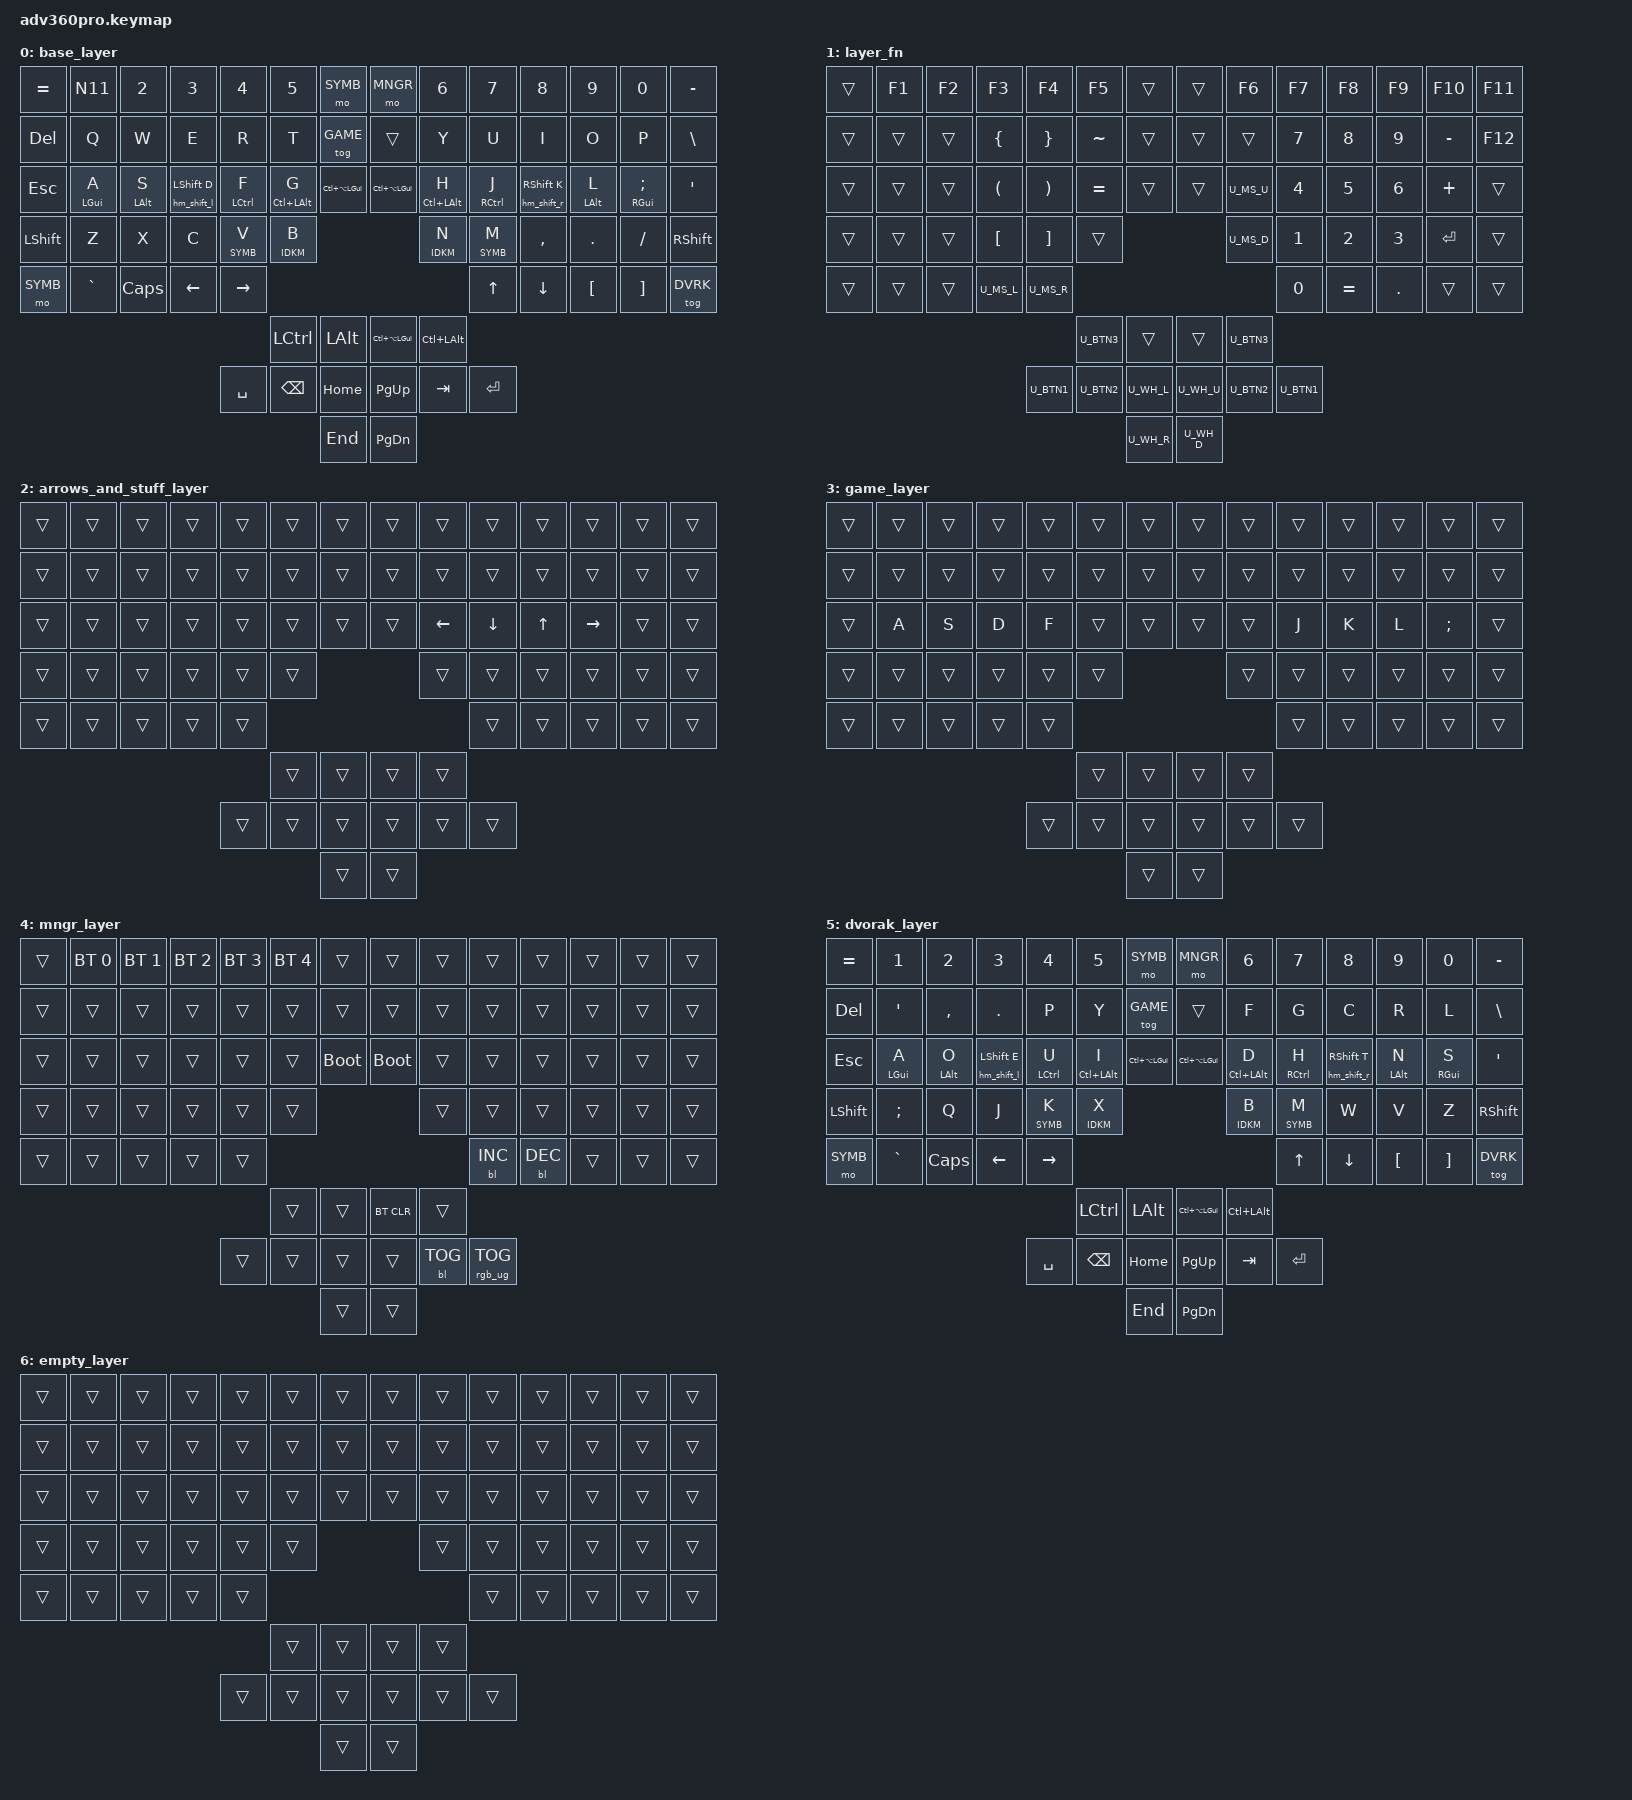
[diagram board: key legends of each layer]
#include <behaviors.dtsi>
#include <dt-bindings/zmk/keys.h>
#include <dt-bindings/zmk/bt.h>
#include <dt-bindings/zmk/outputs.h>
#include <dt-bindings/zmk/rgb.h>
#include <dt-bindings/zmk/backlight.h>
#include "includes/behaviours_homerow_mods.dtsi"

/* definitions for mouse layer */
#include "mouse.dtsi"

#define ___ &trans
#define DFLT 0
#define SYMB 1
#define IDKM 2
#define GAME 3
#define MNGR 4
#define DVRK 5

/ {
    /* remove unused keys from layout and move thumb cluster to bottom */
    chosen {
        zmk,matrix_transform = &urobs_transform;
    };

    keymap {
        compatible = "zmk,keymap";

        base_layer {
            bindings = <
// ╭────────────────────┬────────────────────┬────────────────────┬────────────────────┬────────────────────┬────────────────────┬────────────────────╮ ╭────────────────────┬────────────────────┬────────────────────┬────────────────────┬────────────────────┬────────────────────┬────────────────────╮
    &kp EQUAL            &kp N11               &kp N2               &kp N3               &kp N4               &kp N5               &mo SYMB               &mo MNGR             &kp N6                &kp N7              &kp N8               &kp N9               &kp N0               &kp MINUS
// ├────────────────────┼────────────────────┼────────────────────┼────────────────────┼────────────────────┼────────────────────┼────────────────────┤ ├────────────────────┼────────────────────┼────────────────────┼────────────────────┼────────────────────┼────────────────────┼────────────────────┤
    &kp DEL              &kp Q                &kp W                 &kp E               &kp R                &kp T                &tog GAME              ___                  &kp Y                &kp U                &kp I                &kp O                &kp P                &kp BSLH
// ├────────────────────┼────────────────────┼────────────────────┼────────────────────┼────────────────────┼────────────────────┼────────────────────┤ ├────────────────────┼────────────────────┼────────────────────┼────────────────────┼────────────────────┼────────────────────┼────────────────────┤
    &kp ESC              &hm_l LGUI A         &hm_l LALT S         &hm_shift_l LSHFT D  &hm_l LCTRL F        &hm_l LC(LALT) G     &kp LC(LA(LGUI))       &kp LC(LA(LGUI))     &hm_r LC(LALT) H     &hm_r RCTRL J        &hm_shift_r RSHFT K  &hm_r LALT L         &hm_r RGUI SEMI      &kp SQT
// ├────────────────────┼────────────────────┼────────────────────┼────────────────────┼────────────────────┼────────────────────┴────────────────────╯ ╰────────────────────┼────────────────────┼────────────────────┼────────────────────┼────────────────────┼────────────────────┼────────────────────┤
    &kp LSHFT            &kp Z                &kp X                &kp C                &lt_l SYMB V         &lt_l IDKM B                                                     &lt_r IDKM N         &lt_r SYMB M         &kp COMMA            &kp DOT              &kp FSLH             &kp RSHFT
// ├────────────────────┼────────────────────┼────────────────────┼────────────────────┼────────────────────┼────────────────────╯                                           ╰────────────────────┼────────────────────┼────────────────────┼────────────────────┼────────────────────┼────────────────────┤
    &mo SYMB            &kp GRAVE             &kp CAPS              &kp LEFT             &kp RIGHT                                                                                                 &kp UP               &kp DOWN             &kp LBKT             &kp RBKT             &tog DVRK
// ╰────────────────────┴────────────────────┴────────────────────┴────────────────────┴────────────────────╯                                                                                     ╰────────────────────┴────────────────────┴────────────────────┴────────────────────┴────────────────────╯
//                                                                                                          ╭────────────────────┬────────────────────╮ ╭────────────────────┬────────────────────╮
                                                                                                             &kp LCTRL            &kp LALT               &kp LC(LA(LGUI))     &kp LC(LALT)
//                                                                                     ╭────────────────────┼────────────────────┼────────────────────┤ ├────────────────────┼────────────────────┼────────────────────╮
                                                                                         &kp SPACE           &kp BSPC             &kp HOME                &kp PG_UP           &kp TAB               &kp ENTER
//                                                                                     │                    │                    ├────────────────────┤ ├────────────────────┤                    │                    │
                                                                                                                                  &kp END                 &kp PG_DN
//                                                                                     ╰────────────────────┴────────────────────┴────────────────────╯ ╰────────────────────┴────────────────────┴────────────────────╯
            >;
        };

        layer_fn {
            bindings = <
// ╭────────────────────┬────────────────────┬────────────────────┬────────────────────┬────────────────────┬────────────────────┬────────────────────╮ ╭────────────────────┬────────────────────┬────────────────────┬────────────────────┬────────────────────┬────────────────────┬────────────────────╮
    ___                  &kp F1               &kp F2               &kp F3               &kp F4               &kp F5               ___                    ___                  &kp F6               &kp F7               &kp F8               &kp F9               &kp F10              &kp F11
// ├────────────────────┼────────────────────┼────────────────────┼────────────────────┼────────────────────┼────────────────────┼────────────────────┤ ├────────────────────┼────────────────────┼────────────────────┼────────────────────┼────────────────────┼────────────────────┼────────────────────┤
    ___                  ___                  ___                  &kp LBRC             &kp RBRC             &kp TILDE            ___                    ___                  ___                  &kp N7               &kp N8               &kp N9               &kp MINUS            &kp F12
// ├────────────────────┼────────────────────┼────────────────────┼────────────────────┼────────────────────┼────────────────────┼────────────────────┤ ├────────────────────┼────────────────────┼────────────────────┼────────────────────┼────────────────────┼────────────────────┼────────────────────┤
    ___                  ___                  ___                  &kp LPAR             &kp RPAR             &kp EQUAL            ___                    ___                  U_MS_U               &kp N4               &kp N5               &kp N6               &kp PLUS             ___
// ├────────────────────┼────────────────────┼────────────────────┼────────────────────┼────────────────────┼────────────────────┴────────────────────╯ ╰────────────────────┼────────────────────┼────────────────────┼────────────────────┼────────────────────┼────────────────────┼────────────────────┤
    ___                  ___                  ___                  &kp LBKT             &kp RBKT             ___                                                              U_MS_D               &kp N1               &kp N2               &kp N3               &kp ENTER            ___
// ├────────────────────┼────────────────────┼────────────────────┼────────────────────┼────────────────────┼────────────────────╯                                           ╰────────────────────┼────────────────────┼────────────────────┼────────────────────┼────────────────────┼────────────────────┤
    ___                  ___                  ___                  U_MS_L               U_MS_R                                                                                                     &kp N0               &kp EQUAL            &kp DOT              ___                  ___
// ╰────────────────────┴────────────────────┴────────────────────┴────────────────────┴────────────────────╯                                                                                     ╰────────────────────┴────────────────────┴────────────────────┴────────────────────┴────────────────────╯
//                                                                                                          ╭────────────────────┬────────────────────╮ ╭────────────────────┬────────────────────╮
                                                                                                             U_BTN3               ___                    ___                  U_BTN3
//                                                                                     ╭────────────────────┼────────────────────┼────────────────────┤ ├────────────────────┼────────────────────┼────────────────────╮
                                                                                         U_BTN1              U_BTN2               U_WH_L                 U_WH_U               U_BTN2                U_BTN1
//                                                                                     │                    │                    ├────────────────────┤ ├────────────────────┤                    │                    │
                                                                                                                                  U_WH_R                 U_WH_D
//                                                                                     ╰────────────────────┴────────────────────┴────────────────────╯ ╰────────────────────┴────────────────────┴────────────────────╯
            >;
        };

// wtf else goes on this layer? i only need arrows for a couple things and the thumb arrows are goofy ahh
        arrows_and_stuff_layer {
            bindings = <
// ╭────────────────────┬────────────────────┬────────────────────┬────────────────────┬────────────────────┬────────────────────┬────────────────────╮ ╭────────────────────┬────────────────────┬────────────────────┬────────────────────┬────────────────────┬────────────────────┬────────────────────╮
    ___                  ___                  ___                  ___                  ___                  ___                  ___                    ___                  ___                  ___                  ___                  ___                  ___                  ___
// ├────────────────────┼────────────────────┼────────────────────┼────────────────────┼────────────────────┼────────────────────┼────────────────────┤ ├────────────────────┼────────────────────┼────────────────────┼────────────────────┼────────────────────┼────────────────────┼────────────────────┤
    ___                  ___                  ___                  ___                  ___                  ___                  ___                    ___                  ___                  ___                  ___                  ___                  ___                  ___
// ├────────────────────┼────────────────────┼────────────────────┼────────────────────┼────────────────────┼────────────────────┼────────────────────┤ ├────────────────────┼────────────────────┼────────────────────┼────────────────────┼────────────────────┼────────────────────┼────────────────────┤
    ___                  ___                  ___                  ___                  ___                  ___                  ___                    ___                  &kp LEFT             &kp DOWN             &kp UP               &kp RIGHT            ___                  ___
// ├────────────────────┼────────────────────┼────────────────────┼────────────────────┼────────────────────┼────────────────────┴────────────────────╯ ╰────────────────────┼────────────────────┼────────────────────┼────────────────────┼────────────────────┼────────────────────┼────────────────────┤
    ___                  ___                  ___                  ___                  ___                  ___                                                              ___                  ___                  ___                  ___                  ___                  ___
// ├────────────────────┼────────────────────┼────────────────────┼────────────────────┼────────────────────┼────────────────────╯                                           ╰────────────────────┼────────────────────┼────────────────────┼────────────────────┼────────────────────┼────────────────────┤
    ___                  ___                  ___                  ___                  ___                                                                                                        ___                  ___                  ___                  ___                  ___
// ╰────────────────────┴────────────────────┴────────────────────┴────────────────────┴────────────────────╯                                                                                     ╰────────────────────┴────────────────────┴────────────────────┴────────────────────┴────────────────────╯
//                                                                                                          ╭────────────────────┬────────────────────╮ ╭────────────────────┬────────────────────╮
                                                                                                             ___                  ___                    ___                  ___
//                                                                                     ╭────────────────────┼────────────────────┼────────────────────┤ ├────────────────────┼────────────────────┼────────────────────╮
                                                                                         ___                 ___                  ___                    ___                  ___                   ___
//                                                                                     │                    │                    ├────────────────────┤ ├────────────────────┤                    │                    │
                                                                                                                                  ___                    ___
//                                                                                     ╰────────────────────┴────────────────────┴────────────────────╯ ╰────────────────────┴────────────────────┴────────────────────╯
            >;
        };



// game layer just gets rid of home row mods because thats cancer for playing games
        game_layer {
            bindings = <
// ╭────────────────────┬────────────────────┬────────────────────┬────────────────────┬────────────────────┬────────────────────┬────────────────────╮ ╭────────────────────┬────────────────────┬────────────────────┬────────────────────┬────────────────────┬────────────────────┬────────────────────╮
    ___                  ___                  ___                  ___                  ___                  ___                  ___                    ___                  ___                  ___                  ___                  ___                  ___                  ___
// ├────────────────────┼────────────────────┼────────────────────┼────────────────────┼────────────────────┼────────────────────┼────────────────────┤ ├────────────────────┼────────────────────┼────────────────────┼────────────────────┼────────────────────┼────────────────────┼────────────────────┤
    ___                  ___                  ___                  ___                  ___                  ___                  ___                    ___                  ___                  ___                  ___                  ___                  ___                  ___
// ├────────────────────┼────────────────────┼────────────────────┼────────────────────┼────────────────────┼────────────────────┼────────────────────┤ ├────────────────────┼────────────────────┼────────────────────┼────────────────────┼────────────────────┼────────────────────┼────────────────────┤
    ___                  &kp A                &kp S                &kp D                &kp F                ___                  ___                    ___                  ___                  &kp J                &kp K                &kp L                &kp SEMI             ___
// ├────────────────────┼────────────────────┼────────────────────┼────────────────────┼────────────────────┼────────────────────┴────────────────────╯ ╰────────────────────┼────────────────────┼────────────────────┼────────────────────┼────────────────────┼────────────────────┼────────────────────┤
    ___                  ___                  ___                  ___                  ___                  ___                                                              ___                  ___                  ___                  ___                  ___                  ___
// ├────────────────────┼────────────────────┼────────────────────┼────────────────────┼────────────────────┼────────────────────╯                                           ╰────────────────────┼────────────────────┼────────────────────┼────────────────────┼────────────────────┼────────────────────┤
    ___                  ___                  ___                  ___                  ___                                                                                                        ___                  ___                  ___                  ___                  ___
// ╰────────────────────┴────────────────────┴────────────────────┴────────────────────┴────────────────────╯                                                                                     ╰────────────────────┴────────────────────┴────────────────────┴────────────────────┴────────────────────╯
//                                                                                                          ╭────────────────────┬────────────────────╮ ╭────────────────────┬────────────────────╮
                                                                                                             ___                  ___                    ___                  ___
//                                                                                     ╭────────────────────┼────────────────────┼────────────────────┤ ├────────────────────┼────────────────────┼────────────────────╮
                                                                                         ___                 ___                  ___                    ___                  ___                   ___
//                                                                                     │                    │                    ├────────────────────┤ ├────────────────────┤                    │                    │
                                                                                                                                  ___                    ___
//                                                                                     ╰────────────────────┴────────────────────┴────────────────────╯ ╰────────────────────┴────────────────────┴────────────────────╯
            >;
        };

        mngr_layer {
            bindings = <
// ╭────────────────────┬────────────────────┬────────────────────┬────────────────────┬────────────────────┬────────────────────┬────────────────────╮ ╭────────────────────┬────────────────────┬────────────────────┬────────────────────┬────────────────────┬────────────────────┬────────────────────╮
    ___                  &bt BT_SEL 0         &bt BT_SEL 1         &bt BT_SEL 2         &bt BT_SEL 3         &bt BT_SEL 4         ___                    ___                  ___                  ___                  ___                  ___                  ___                  ___
// ├────────────────────┼────────────────────┼────────────────────┼────────────────────┼────────────────────┼────────────────────┼────────────────────┤ ├────────────────────┼────────────────────┼────────────────────┼────────────────────┼────────────────────┼────────────────────┼────────────────────┤
    ___                  ___                  ___                  ___                  ___                  ___                  ___                    ___                  ___                  ___                  ___                  ___                  ___                  ___
// ├────────────────────┼────────────────────┼────────────────────┼────────────────────┼────────────────────┼────────────────────┼────────────────────┤ ├────────────────────┼────────────────────┼────────────────────┼────────────────────┼────────────────────┼────────────────────┼────────────────────┤
    ___                  ___                  ___                  ___                  ___                  ___                  &bootloader            &bootloader           ___                  ___                  ___                  ___                  ___                  ___
// ├────────────────────┼────────────────────┼────────────────────┼────────────────────┼────────────────────┼────────────────────┴────────────────────╯ ╰────────────────────┼────────────────────┼────────────────────┼────────────────────┼────────────────────┼────────────────────┼────────────────────┤
    ___                  ___                  ___                  ___                  ___                  ___                                                              ___                  ___                  ___                  ___                  ___                  ___
// ├────────────────────┼────────────────────┼────────────────────┼────────────────────┼────────────────────┼────────────────────╯                                           ╰────────────────────┼────────────────────┼────────────────────┼────────────────────┼────────────────────┼────────────────────┤
    ___                  ___                  ___                  ___                  ___                                                                                                        &bl BL_INC           &bl BL_DEC           ___                  ___                  ___
// ╰────────────────────┴────────────────────┴────────────────────┴────────────────────┴────────────────────╯                                                                                     ╰────────────────────┴────────────────────┴────────────────────┴────────────────────┴────────────────────╯
//                                                                                                          ╭────────────────────┬────────────────────╮ ╭────────────────────┬────────────────────╮
                                                                                                             ___                  ___                    &bt BT_CLR           ___
//                                                                                     ╭────────────────────┼────────────────────┼────────────────────┤ ├────────────────────┼────────────────────┼────────────────────╮
                                                                                         ___                 ___                  ___                    ___                  &bl BL_TOG           &rgb_ug RGB_TOG
//                                                                                     │                    │                    ├────────────────────┤ ├────────────────────┤                    │                    │
                                                                                                                                  ___                    ___
//                                                                                     ╰────────────────────┴────────────────────┴────────────────────╯ ╰────────────────────┴────────────────────┴────────────────────╯
            >;
        };

        dvorak_layer {
            bindings = <
// ╭────────────────────┬────────────────────┬────────────────────┬────────────────────┬────────────────────┬────────────────────┬────────────────────╮ ╭────────────────────┬────────────────────┬────────────────────┬────────────────────┬────────────────────┬────────────────────┬────────────────────╮
    &kp EQUAL            &kp N1               &kp N2               &kp N3               &kp N4               &kp N5               &mo SYMB               &mo MNGR             &kp N6                &kp N7              &kp N8               &kp N9               &kp N0               &kp MINUS
// ├────────────────────┼────────────────────┼────────────────────┼────────────────────┼────────────────────┼────────────────────┼────────────────────┤ ├────────────────────┼────────────────────┼────────────────────┼────────────────────┼────────────────────┼────────────────────┼────────────────────┤
    &kp DEL              &kp SQT              &kp COMMA            &kp DOT              &kp P                &kp Y                &tog GAME              ___                  &kp F                &kp G                &kp C                &kp R                &kp L                &kp BSLH
// ├────────────────────┼────────────────────┼────────────────────┼────────────────────┼────────────────────┼────────────────────┼────────────────────┤ ├────────────────────┼────────────────────┼────────────────────┼────────────────────┼────────────────────┼────────────────────┼────────────────────┤
    &kp ESC              &hm_l LGUI A         &hm_l LALT O         &hm_shift_l LSHFT E  &hm_l LCTRL U        &hm_l LC(LALT) I     &kp LC(LA(LGUI))       &kp LC(LA(LGUI))     &hm_r LC(LALT) D     &hm_r RCTRL H        &hm_shift_r RSHFT T  &hm_r LALT N         &hm_r RGUI S         &kp SQT
// ├────────────────────┼────────────────────┼────────────────────┼────────────────────┼────────────────────┼────────────────────┴────────────────────╯ ╰────────────────────┼────────────────────┼────────────────────┼────────────────────┼────────────────────┼────────────────────┼────────────────────┤
    &kp LSHFT            &kp SEMI             &kp Q                &kp J                &lt_l SYMB K         &lt_l IDKM X                                                     &lt_r IDKM B         &lt_r SYMB M         &kp W                &kp V                &kp Z                &kp RSHFT
// ├────────────────────┼────────────────────┼────────────────────┼────────────────────┼────────────────────┼────────────────────╯                                           ╰────────────────────┼────────────────────┼────────────────────┼────────────────────┼────────────────────┼────────────────────┤
    &mo SYMB            &kp GRAVE             &kp CAPS              &kp LEFT             &kp RIGHT                                                                                                 &kp UP               &kp DOWN             &kp LBKT             &kp RBKT             &tog DVRK
// ╰────────────────────┴────────────────────┴────────────────────┴────────────────────┴────────────────────╯                                                                                     ╰────────────────────┴────────────────────┴────────────────────┴────────────────────┴────────────────────╯
//                                                                                                          ╭────────────────────┬────────────────────╮ ╭────────────────────┬────────────────────╮
                                                                                                             &kp LCTRL            &kp LALT               &kp LC(LA(LGUI))     &kp LC(LALT)
//                                                                                     ╭────────────────────┼────────────────────┼────────────────────┤ ├────────────────────┼────────────────────┼────────────────────╮
                                                                                         &kp SPACE           &kp BSPC             &kp HOME                &kp PG_UP           &kp TAB               &kp ENTER
//                                                                                     │                    │                    ├────────────────────┤ ├────────────────────┤                    │                    │
                                                                                                                                  &kp END                 &kp PG_DN
//                                                                                     ╰────────────────────┴────────────────────┴────────────────────╯ ╰────────────────────┴────────────────────┴────────────────────╯
            >;
        };

        empty_layer {
            bindings = <
// ╭────────────────────┬────────────────────┬────────────────────┬────────────────────┬────────────────────┬────────────────────┬────────────────────╮ ╭────────────────────┬────────────────────┬────────────────────┬────────────────────┬────────────────────┬────────────────────┬────────────────────╮
    ___                  ___                  ___                  ___                  ___                  ___                  ___                    ___                  ___                  ___                  ___                  ___                  ___                  ___
// ├────────────────────┼────────────────────┼────────────────────┼────────────────────┼────────────────────┼────────────────────┼────────────────────┤ ├────────────────────┼────────────────────┼────────────────────┼────────────────────┼────────────────────┼────────────────────┼────────────────────┤
    ___                  ___                  ___                  ___                  ___                  ___                  ___                    ___                  ___                  ___                  ___                  ___                  ___                  ___
// ├────────────────────┼────────────────────┼────────────────────┼────────────────────┼────────────────────┼────────────────────┼────────────────────┤ ├────────────────────┼────────────────────┼────────────────────┼────────────────────┼────────────────────┼────────────────────┼────────────────────┤
    ___                  ___                  ___                  ___                  ___                  ___                  ___                    ___                  ___                  ___                  ___                  ___                  ___                  ___
// ├────────────────────┼────────────────────┼────────────────────┼────────────────────┼────────────────────┼────────────────────┴────────────────────╯ ╰────────────────────┼────────────────────┼────────────────────┼────────────────────┼────────────────────┼────────────────────┼────────────────────┤
    ___                  ___                  ___                  ___                  ___                  ___                                                              ___                  ___                  ___                  ___                  ___                  ___
// ├────────────────────┼────────────────────┼────────────────────┼────────────────────┼────────────────────┼────────────────────╯                                           ╰────────────────────┼────────────────────┼────────────────────┼────────────────────┼────────────────────┼────────────────────┤
    ___                  ___                  ___                  ___                  ___                                                                                                        ___                  ___                  ___                  ___                  ___
// ╰────────────────────┴────────────────────┴────────────────────┴────────────────────┴────────────────────╯                                                                                     ╰────────────────────┴────────────────────┴────────────────────┴────────────────────┴────────────────────╯
//                                                                                                          ╭────────────────────┬────────────────────╮ ╭────────────────────┬────────────────────╮
                                                                                                             ___                  ___                    ___                  ___
//                                                                                     ╭────────────────────┼────────────────────┼────────────────────┤ ├────────────────────┼────────────────────┼────────────────────╮
                                                                                         ___                 ___                  ___                    ___                  ___                   ___
//                                                                                     │                    │                    ├────────────────────┤ ├────────────────────┤                    │                    │
                                                                                                                                  ___                    ___
//                                                                                     ╰────────────────────┴────────────────────┴────────────────────╯ ╰────────────────────┴────────────────────┴────────────────────╯
            >;
        };
    };

};
